# RK3399-AP register map
File version: 1
Rockchip RK3399 for AP CPU
CPU: CA7 r0p1, little endian, MPU, FPU, I-cache, D-cache, VTOR, 4 interrupt priority bits, 32 interrupts
Registers are 32-bit, read-write, reset 0x0 unless marked. A register's access mark holds for its fields unless they carry their own. Offsets are from the block's base; lines under a group give offsets from that group; [hi:lo] are bit positions; {n}, {i} and the like mark numbered series; 'fields as' and 'values as' point back to an identical list; <NAME> marks a mode.

## Memory map
0xF8000000 PCIE
0xFE300000 GMAC
0xFE320000 SDMMC
0xFE330000 EMMCCORE
0xFF100000 SARADC
0xFF110000 I2C1
0xFF120000 I2C2
0xFF130000 I2C3
0xFF140000 I2C5
0xFF150000 I2C6
0xFF160000 I2C7
0xFF180000 UART0
0xFF190000 UART1
0xFF1A0000 UART2
0xFF1B0000 UART3
0xFF1C0000 SPI0
0xFF1D0000 SPI1
0xFF1E0000 SPI2
0xFF1F0000 SPI4
0xFF200000 SPI5
0xFF260000 TSADC
0xFF310000 PMU
0xFF320000 PMUGRF
0xFF330000 PMUSGRF
0xFF350000 SPI3
0xFF360000 PMUTIMER0
0xFF360020 PMUTIMER1
0xFF370000 UART4
0xFF380000 WDT2
0xFF390000 MAILBOX1
0xFF3C0000 I2C0
0xFF3D0000 I2C4
0xFF3E0000 I2C8
0xFF420000 PWM
0xFF620000 CIC
0xFF630000 DDRMON
0xFF670800 IEP_MMU
0xFF690000 EFUSE0
0xFF6B0000 MAILBOX0
0xFF6D0000 DMAC0
0xFF6E0000 DMAC1
0xFF720000 GPIO0
0xFF730000 GPIO1
0xFF750000 PMUCRU
0xFF760000 CRU
0xFF770000 GRF
0xFF780000 GPIO2
0xFF788000 GPIO3
0xFF790000 GPIO4
0xFF840000 WDT1
0xFF848000 WDT0
0xFF850000 TIMER0
0xFF850020 TIMER1
0xFF850040 TIMER2
0xFF850060 TIMER3
0xFF850080 TIMER4
0xFF850100 TIMER5
0xFF858000 TIMER6
0xFF858020 TIMER7
0xFF858040 TIMER8
0xFF858060 TIMER9
0xFF858080 TIMER10
0xFF858100 TIMER11
0xFF860000 STIMER0
0xFF860020 STIMER1
0xFF860040 STIMER2
0xFF860060 STIMER3
0xFF860080 STIMER4
0xFF860100 STIMER5
0xFF868000 STIMER6
0xFF868020 STIMER7
0xFF868040 STIMER8
0xFF868060 STIMER9
0xFF868080 STIMER10
0xFF868100 STIMER11
0xFF870000 SPDIF
0xFF880000 I2S0
0xFF890000 I2S1
0xFF8A0000 I2S2
0xFF8F0300 VOPL_MMU
0xFF900300 VOPB_MMU
0xFF914000 ISP0_MMU0
0xFF915000 ISP0_MMU1
0xFF924000 ISP1_MMU0
0xFF925000 ISP1_MMU1
0xFF930000 HDCP_MMU
0xFFA80800 PI0
0xFFA84000 MSCH0
0xFFA86000 CCI_PROBE_MSCH0
0xFFA86400 GPU_PROBE_MSCH0E
0xFFA86800 PERIHP_PROBE_MSCH0
0xFFA86C00 PERILP_PROBE_MSCH0
0xFFA87000 VIDEO_PROBE_MSCH0
0xFFA87400 VIO0_PROBE_MSCH0
0xFFA87800 VIO1_PROBE_MSCH0
0xFFA88800 PI1
0xFFA8C000 MSCH1
0xFFA8E000 CCI_PROBE_MSCH1
0xFFA8E400 GPU_PROBE_MSCH1
0xFFA8E800 PERIHP_PROBE_MSCH1
0xFFA8EC00 PERILP_PROBE_MSCH1
0xFFA8F000 VIDEO_PROBE_MSCH1
0xFFA8F400 VIO0_PROBE_MSCH1
0xFFA8F800 VIO1_PROBE_MSCH1
0xFFB00000 CCI500
0xFFFA0000 EFUSE1

## CCI_PROBE_MSCH0
Base 0xFFA86000
Same registers: GPU_PROBE_MSCH0E 0xFFA86400, PERIHP_PROBE_MSCH0 0xFFA86800, PERILP_PROBE_MSCH0 0xFFA86C00, VIDEO_PROBE_MSCH0 0xFFA87000, VIO0_PROBE_MSCH0 0xFFA87400, VIO1_PROBE_MSCH0 0xFFA87800, CCI_PROBE_MSCH1 0xFFA8E000, GPU_PROBE_MSCH1 0xFFA8E400, PERIHP_PROBE_MSCH1 0xFFA8E800, PERILP_PROBE_MSCH1 0xFFA8EC00, VIDEO_PROBE_MSCH1 0xFFA8F000, VIO0_PROBE_MSCH1 0xFFA8F400, VIO1_PROBE_MSCH1 0xFFA8F800
0x00 PROBE_Id_CoreId access not given reset 0xD867006 — Core ID register
0x04 PROBE_Id_RevisionId access not given reset 0x1AA00 — Revision ID register
0x08 PROBE_MainCtl access not given — Register MainCtl contains probe global control bits.
0x0C PROBE_CfgCtl access not given — Register CfgCtl contains global enable and active bits.
0x24 PROBE_StatPeriod access not given — Statistics Period
0x28 PROBE_StatGo access not given — Statistics start to dump
{0x138+0x14*i} PROBE_Counters_{i}_Src access not given (i=0..3) — Register CntSrc indicates the event source.
{0x13C+0x14*i} PROBE_Counters_{i}_Val access not given (i=0..3) — Registers Counters_M_Val contain the statistics counter values.

## WDT2
Base 0xFF380000
Same registers: WDT1 0xFF840000, WDT0 0xFF848000
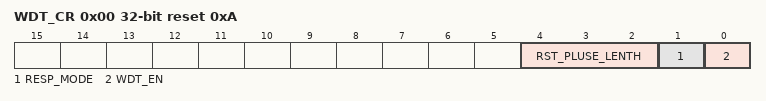
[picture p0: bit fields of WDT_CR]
0x00 WDT_CR reset 0xA — Control Register
  [4:2] RST_PLUSE_LENTH — Reset pulse length. This is used to select the number of pclk cycles for which the system reset stays asserted. 000: 2 pclk cycles 001: 4 pclk cycles 010: 8 pclk cycles 011: 16 pclk cycles 100: 32 pclk cycles 101: 64 pclk cycles 110: 128 pclk cycles 111: 256 pclk cycles
  [1] RESP_MODE — Response mode. Selects the output response generated to a timeout. 0: Generate a system reset. 1: First generate an interrupt and if it is not cleared by the time a second timeout occurs then generate a system reset.
  [0] WDT_EN — Writable when the configuration parameter WDT_ALWAYS_EN=0, otherwise, it is readable. This bit is used to enable and disable the watchdog. When disabled, the counter dose not decrement .Thus, no interrupt or system reset is generated. Once this bit has been enabled, it can be cleared only by a system reset. 0: WDT disabled; 1: WDT enabled.
0x04 WDT_TORR — Timeout range Register
  [3:0] TIMEOUT_PERIOD — Timeout period. This field is used to select the timeout period from which the watchdog counter restarts. A change of the timeout period takes effect only after the next counter restart (kick). The range of values available for a 32-bit watchdog counter are: 0000: 0x0000ffff 0001: 0x0001ffff 0010: 0x0003ffff 0011: 0x0007ffff 0100: 0x000fffff 0101: 0x001fffff 0110: 0x003fffff 0111: 0x007fffff 1000: 0x00ffffff 1001: 0x01ffffff 1010: 0x03ffffff 1011: 0x07ffffff 1100: 0x0fffffff 1101: 0x1fffffff 1110: 0x3fffffff 1111: 0x7fffffff
0x08 WDT_CCVR ro — Current counter value Register
  [31:0] CUR_CNT — Current counter value This register, when read, is the current value of the internal counter. This value is read coherently whenever it is read
0x0C WDT_CRR — Counter restart Register
  [7:0] CNT_RESTART write-1-clears — Counter restart This register is used to restart the WDT counter. As a safety feature to prevent accidental restarts, the value 0x76 must be written. A restart also clears the WDT interrupt. Reading this register returns zero.
0x10 WDT_STAT ro — Interrupt status Register
  [0] WDT_STATUS — This register shows the interrupt status of the WDT. 1: Interrupt is active regardless of polarity; 0: Interrupt is inactive.
0x14 WDT_EOI ro — Interrupt clear Register
  [0] WDT_INT_CLR read-clears — Clears the watchdog interrupt. This can be used to clear the interrupt without restarting the watchdog counter.
